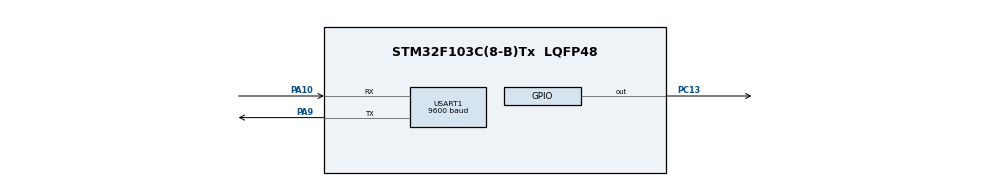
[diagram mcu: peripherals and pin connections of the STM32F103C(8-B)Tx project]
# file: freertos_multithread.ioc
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FREERTOS.Tasks01=ledFlash,0,128,blinkLed,Default,NULL,Dynamic,NULL,NULL;sendText,-3,128,sendtext,Default,NULL,Dynamic,NULL,NULL
FREERTOS.configUSE_NEWLIB_REENTRANT=1
Mcu.Family=STM32F1
Mcu.Name=STM32F103C(8-B)Tx
Mcu.Package=LQFP48
NVIC.PriorityGroup=NVIC_PRIORITYGROUP_4
NVIC.TIM2_IRQn=true\:15\:0\:false\:false\:true\:false\:false\:true\:true
NVIC.TimeBase=TIM2_IRQn
NVIC.TimeBaseIP=TIM2
PA10.Mode=Asynchronous
PA10.Signal=USART1_RX
PA13.Mode=Serial_Wire
PA13.Signal=SYS_JTMS-SWDIO
PA14.Mode=Serial_Wire
PA14.Signal=SYS_JTCK-SWCLK
PA9.Mode=Asynchronous
PA9.Signal=USART1_TX
PC13-TAMPER-RTC.Signal=GPIO_Output
PC14-OSC32_IN.Mode=LSE-External-Oscillator
PC14-OSC32_IN.Signal=RCC_OSC32_IN
PC15-OSC32_OUT.Mode=LSE-External-Oscillator
PC15-OSC32_OUT.Signal=RCC_OSC32_OUT
PD0-OSC_IN.Mode=HSE-External-Oscillator
PD0-OSC_IN.Signal=RCC_OSC_IN
PD1-OSC_OUT.Mode=HSE-External-Oscillator
PD1-OSC_OUT.Signal=RCC_OSC_OUT
ProjectManager.HeapSize=0x200
ProjectManager.StackSize=0x400
ProjectManager.TargetToolchain=STM32CubeIDE
RCC.APB1Freq_Value=8000000
RCC.APB2Freq_Value=8000000
USART1.BaudRate=9600
USART1.VirtualMode=VM_ASYNC
VP_FREERTOS_VS_CMSIS_V1.Mode=CMSIS_V1
VP_SYS_VS_tim2.Mode=TIM2
board=custom

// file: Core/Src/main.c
/* USER CODE BEGIN Header */
/**
  ******************************************************************************
  * @file           : main.c
  * @brief          : Main program body
  ******************************************************************************
  * @attention
  *
  * Copyright (c) 2023 STMicroelectronics.
  * All rights reserved.
  *
  * This software is licensed under terms that can be found in the LICENSE file
  * in the root directory of this software component.
  * If no LICENSE file comes with this software, it is provided AS-IS.
  *
  ******************************************************************************
  */
/* USER CODE END Header */
#include "main.h"
#include "cmsis_os.h"

UART_HandleTypeDef huart1;

osThreadId ledFlashHandle;
osThreadId sendTextHandle;

void SystemClock_Config(void);
static void MX_GPIO_Init(void);
static void MX_USART1_UART_Init(void);
void blinkLed(void const * argument);
void sendtext(void const * argument);

int main(void)
{

  /* MCU Configuration--------------------------------------------------------*/

  /* Reset of all peripherals, Initializes the Flash interface and the Systick. */
  HAL_Init();

  /* Configure the system clock */
  SystemClock_Config();

  /* Initialize all configured peripherals */
  MX_GPIO_Init();
  MX_USART1_UART_Init();

  /* Create the thread(s) */
  /* definition and creation of ledFlash */
  osThreadDef(ledFlash, blinkLed, osPriorityNormal, 0, 128);
  ledFlashHandle = osThreadCreate(osThread(ledFlash), NULL);

  /* definition and creation of sendText */
  osThreadDef(sendText, sendtext, osPriorityIdle, 0, 128);
  sendTextHandle = osThreadCreate(osThread(sendText), NULL);

  /* Start scheduler */
  osKernelStart();

  /* We should never get here as control is now taken by the scheduler */
  /* Infinite loop */
  while (1)
  {

  }
}

void SystemClock_Config(void)
{
  RCC_OscInitTypeDef RCC_OscInitStruct = {0};
  RCC_ClkInitTypeDef RCC_ClkInitStruct = {0};

  /** Initializes the RCC Oscillators according to the specified parameters
  * in the RCC_OscInitTypeDef structure.
  */
  RCC_OscInitStruct.OscillatorType = RCC_OSCILLATORTYPE_HSI;
  RCC_OscInitStruct.HSIState = RCC_HSI_ON;
  RCC_OscInitStruct.HSICalibrationValue = RCC_HSICALIBRATION_DEFAULT;
  RCC_OscInitStruct.PLL.PLLState = RCC_PLL_NONE;
  if (HAL_RCC_OscConfig(&RCC_OscInitStruct) != HAL_OK)
  {
    Error_Handler();
  }

  /** Initializes the CPU, AHB and APB buses clocks
  */
  RCC_ClkInitStruct.ClockType = RCC_CLOCKTYPE_HCLK|RCC_CLOCKTYPE_SYSCLK
                              |RCC_CLOCKTYPE_PCLK1|RCC_CLOCKTYPE_PCLK2;
  RCC_ClkInitStruct.SYSCLKSource = RCC_SYSCLKSOURCE_HSI;
  RCC_ClkInitStruct.AHBCLKDivider = RCC_SYSCLK_DIV1;
  RCC_ClkInitStruct.APB1CLKDivider = RCC_HCLK_DIV1;
  RCC_ClkInitStruct.APB2CLKDivider = RCC_HCLK_DIV1;

  if (HAL_RCC_ClockConfig(&RCC_ClkInitStruct, FLASH_LATENCY_0) != HAL_OK)
  {
    Error_Handler();
  }
}

static void MX_USART1_UART_Init(void)
{

  huart1.Instance = USART1;
  huart1.Init.BaudRate = 9600;
  huart1.Init.WordLength = UART_WORDLENGTH_8B;
  huart1.Init.StopBits = UART_STOPBITS_1;
  huart1.Init.Parity = UART_PARITY_NONE;
  huart1.Init.Mode = UART_MODE_TX_RX;
  huart1.Init.HwFlowCtl = UART_HWCONTROL_NONE;
  huart1.Init.OverSampling = UART_OVERSAMPLING_16;
  if (HAL_UART_Init(&huart1) != HAL_OK)
  {
    Error_Handler();
  }

}

static void MX_GPIO_Init(void)
{
  GPIO_InitTypeDef GPIO_InitStruct = {0};

  /* GPIO Ports Clock Enable */
  __HAL_RCC_GPIOC_CLK_ENABLE();
  __HAL_RCC_GPIOD_CLK_ENABLE();
  __HAL_RCC_GPIOA_CLK_ENABLE();

  /*Configure GPIO pin Output Level */
  HAL_GPIO_WritePin(GPIOC, GPIO_PIN_13, GPIO_PIN_RESET);

  /*Configure GPIO pin : PC13 */
  GPIO_InitStruct.Pin = GPIO_PIN_13;
  GPIO_InitStruct.Mode = GPIO_MODE_OUTPUT_PP;
  GPIO_InitStruct.Pull = GPIO_NOPULL;
  GPIO_InitStruct.Speed = GPIO_SPEED_FREQ_LOW;
  HAL_GPIO_Init(GPIOC, &GPIO_InitStruct);

}

void blinkLed(void const * argument)
{
  /* USER CODE BEGIN 5 */
  /* Infinite loop */
  for(;;)
  {
	  HAL_GPIO_TogglePin(GPIOC, GPIO_PIN_13);
	  osDelay(1000);
  }
  /* USER CODE END 5 */
}

void sendtext(void const * argument)
{
  /* USER CODE BEGIN sendtext */
   uint8_t message[35] = {'\0'};
   uint8_t num = 0;
  /* Infinite loop */
  for(;;)
  {
	  /* USER CODE END WHILE */
	sprintf(message, "Welcome to lab! Counting = %d\r\n", num);
	HAL_UART_Transmit(&huart1, message, sizeof(message), 100);
	num++;
    osDelay(1000);
  }
  /* USER CODE END sendtext */
}

void HAL_TIM_PeriodElapsedCallback(TIM_HandleTypeDef *htim)
{
  if (htim->Instance == TIM2) {
    HAL_IncTick();
  }
}

void Error_Handler(void)
{
  __disable_irq();
  while (1)
  {
  }
}
